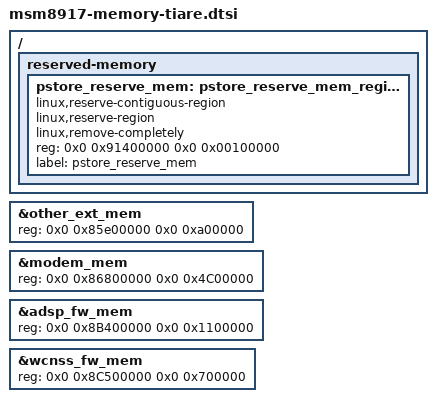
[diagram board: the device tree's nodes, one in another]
/*
 * Copyright (c) 2015-2018, The Linux Foundation. All rights reserved.
 *
 * This program is free software; you can redistribute it and/or modify
 * it under the terms of the GNU General Public License version 2 and
 * only version 2 as published by the Free Software Foundation.
 *
 * This program is distributed in the hope that it will be useful,
 * but WITHOUT ANY WARRANTY; without even the implied warranty of
 * MERCHANTABILITY or FITNESS FOR A PARTICULAR PURPOSE.  See the
 * GNU General Public License for more details.
 */

&other_ext_mem {
	reg = <0x0 0x85e00000 0x0 0xa00000>;
};

&modem_mem {
	reg = <0x0 0x86800000 0x0 0x4C00000>;
};

&adsp_fw_mem {
	reg = <0x0 0x8B400000 0x0 0x1100000>;
};

&wcnss_fw_mem {
	reg = <0x0 0x8C500000 0x0 0x700000>;
};

/ {
	reserved-memory {
		pstore_reserve_mem: pstore_reserve_mem_region@0 {
			linux,reserve-contiguous-region;
			linux,reserve-region;
			linux,remove-completely;
			reg = <0x0 0x91400000 0x0 0x00100000>;
			label = "pstore_reserve_mem";
                };
	};
};
